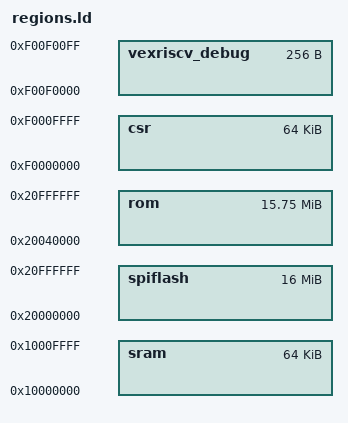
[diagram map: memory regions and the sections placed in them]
MEMORY {
	vexriscv_debug : ORIGIN = 0xf00f0000, LENGTH = 0x00000100
	sram : ORIGIN = 0x10000000, LENGTH = 0x00010000
	spiflash : ORIGIN = 0x20000000, LENGTH = 0x01000000
	rom : ORIGIN = 0x20040000, LENGTH = 0x00fc0000
	csr : ORIGIN = 0xf0000000, LENGTH = 0x00010000
}
